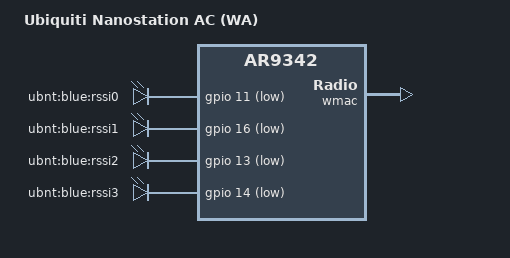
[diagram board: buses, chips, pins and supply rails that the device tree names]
// SPDX-License-Identifier: GPL-2.0-only

#include "ar9342_ubnt_wa_2port.dtsi"

/ {
	compatible = "ubnt,nanostation-ac","ubnt,wa", "qca,ar9342";
	model = "Ubiquiti Nanostation AC (WA)";

	aliases {
		led-boot = &led_rssi3;
		led-failsafe = &led_rssi3;
		led-upgrade = &led_rssi3;
	};

	leds {
		compatible = "gpio-leds";

		rssi0 {
			label = "ubnt:blue:rssi0";
			gpios = <&gpio 11 GPIO_ACTIVE_LOW>;
		};

		rssi1 {
			label = "ubnt:blue:rssi1";
			gpios = <&gpio 16 GPIO_ACTIVE_LOW>;
		};

		rssi2 {
			label = "ubnt:blue:rssi2";
			gpios = <&gpio 13 GPIO_ACTIVE_LOW>;
		};

		led_rssi3: rssi3 {
			label = "ubnt:blue:rssi3";
			gpios = <&gpio 14 GPIO_ACTIVE_LOW>;
		};
	};
};

&wmac {
	status = "okay";

	mtd-cal-data = <&art 0x1000>;
};
